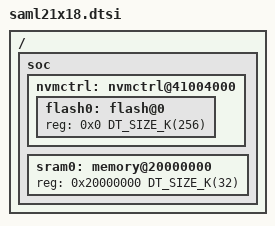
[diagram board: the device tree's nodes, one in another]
#include <mem.h>
#include <atmel/saml21.dtsi>

/ {

    soc {

        nvmctrl: nvmctrl@41004000 {
            flash0: flash@0 {
                reg = <0x0 DT_SIZE_K(256)>;
            };
        };

        sram0: memory@20000000 {
            reg = <0x20000000 DT_SIZE_K(32)>;
        };
    };
};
